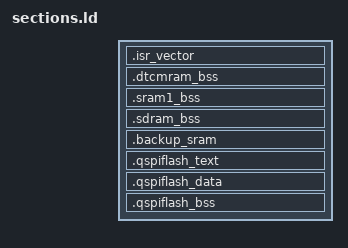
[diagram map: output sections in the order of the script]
/* Stack pointer for Daisy bootloader - MUST be at end of DTCMRAM */
_estack = 0x20020000;

SECTIONS
{
	/* ISR vector table MUST be first in SRAM for Daisy bootloader */
	.isr_vector :
	{
		. = ALIGN(4);
		KEEP(*(.isr_vector))
		. = ALIGN(4);
	} > SRAM

  .dtcmram_bss (NOLOAD) :
	{
		. = ALIGN(4);
		_sdtcmram_bss = .;

		PROVIDE(__dtcmram_bss_start__ = _sdtcmram_bss);
		*(.dtcmram_bss)
		*(.dtcmram_bss*)
		. = ALIGN(4);
		_edtcmram_bss = .;

		PROVIDE(__dtcmram_bss_end__ = _edtcmram_bss);
	} > DTCMRAM

	.sram1_bss (NOLOAD) :
	{
		. = ALIGN(4);
		_ssram1_bss = .;

		PROVIDE(__sram1_bss_start__ = _sram1_bss);
		*(.sram1_bss)
		*(.sram1_bss*)
		. = ALIGN(4);
		_esram1_bss = .;

		PROVIDE(__sram1_bss_end__ = _esram1_bss);
	} > RAM_D2   

	.sdram_bss (NOLOAD) :
	{
		. = ALIGN(4);
		_ssdram_bss = .;

		PROVIDE(__sdram_bss_start = _ssdram_bss);
		*(.sdram_bss)
		*(.sdram_bss*)
		. = ALIGN(4);
		_esdram_bss = .;

		PROVIDE(__sdram_bss_end = _esdram_bss);
	} > SDRAM

		.backup_sram (NOLOAD) :
	{
		. = ALIGN(4);
		_sbackup_sram = .;

		PROVIDE(__backup_sram_start = _sbackup_sram);
		*(.backup_sram)
		*(.backup_sram*)
		. = ALIGN(4);
		_ebackup_sram = .;

		PROVIDE(__backup_sram_end = _ebackup_sram);
	} > BACKUP_SRAM

	.qspiflash_text :
	{
		. = ALIGN(4);
		_sqspiflash_text = .;

		PROVIDE(__qspiflash_text_start = _sqspiflash_text);
		*(.qspiflash_text)
		*(.qspiflash_text*)
		. = ALIGN(4);
		_eqspiflash_text = .;

		PROVIDE(__qspiflash_text_end = _eqspiflash_text);
	} > QSPIFLASH

	.qspiflash_data :
	{
		. = ALIGN(4);
		_sqspiflash_data = .;

		PROVIDE(__qspiflash_data_start = _sqspiflash_data);
		*(.qspiflash_data)
		*(.qspiflash_data*)
		. = ALIGN(4);
		_eqspiflash_data = .;

		PROVIDE(__qspiflash_data_end = _eqspiflash_data);
	} > QSPIFLASH

	.qspiflash_bss (NOLOAD) :
	{
		. = ALIGN(4);
		_sqspiflash_bss = .;

		PROVIDE(__qspiflash_bss_start = _sqspiflash_bss);
		*(.qspiflash_bss)
		*(.qspiflash_bss*)
		. = ALIGN(4);
		_eqspiflash_bss = .;

		PROVIDE(__qspiflash_bss_end = _eqspiflash_bss);
	} > QSPIFLASH
}
